AUTOSAR XML (schema 00049)
standard types defined: Boolean, SInt8, UInt32, Double, boolean, sint32, sint8, uint32, float64
package /Components
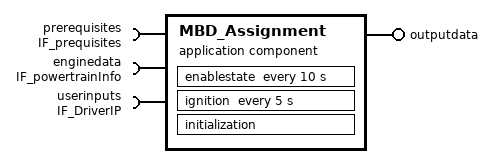
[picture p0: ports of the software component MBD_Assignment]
  application sw component type MBD_Assignment
    require port prerequisites: required-interface=IF_prequisites
      required-com-specs:
        data-element=IF_prequisites/DataElement1, init-value=0
        data-element=IF_prequisites/DataElement2, init-value=stowed
    require port enginedata: required-interface=IF_powertrainInfo
      required-com-specs:
        data-element=IF_powertrainInfo/DataElement1, init-value=neutral
        data-element=IF_powertrainInfo/DataElement2, init-value=0
    require port userinputs: required-interface=IF_DriverIP
      required-com-specs:
        data-element=IF_DriverIP/DataElement1, init-value=0
        data-element=IF_DriverIP/DataElement2, init-value=0
    provide port outputdata: provided-interface=outputdata
      provided-com-specs:
        data-element=outputdata/DataElement1, init-value=0
        data-element=outputdata/DataElement2, init-value=0
    behavior MBD_Assignment_IB: handle-termination-and-restart=NO-SUPPORT
      timing event Event: start-on-event=enablestate, period=10
      timing event Event1: start-on-event=ignition, period=5
      init event Event2: start-on-event=initialization
      implicit-inter-runnable-variables:
        data startenable: category=VALUE, sw-calibration-access=READ-ONLY, type=Boolean, init-value=0
      runnable enablestate
        data-read-access:
          5 x access:
            IN_userinputs_DataElement2: accessed-variable=userinputs.DataElement2
            IN_enginedata_DataElement1: accessed-variable=enginedata.DataElement1
            IN_enginedata_DataElement2: accessed-variable=enginedata.DataElement2
            IN_prerequisites_DataElement1: accessed-variable=prerequisites.DataElement1
            IN_prerequisites_DataElement2: accessed-variable=prerequisites.DataElement2
        written-local-variables:
          access WV_startenable: accessed-variable=startenable
      runnable ignition
        data-read-access:
          access IN_userinputs_DataElement1: accessed-variable=userinputs.DataElement1
        data-write-access:
          access OUT_outputdata_DataElement1: accessed-variable=outputdata.DataElement1
          access OUT_outputdata_DataElement2: accessed-variable=outputdata.DataElement2
        read-local-variables:
          access RV_startenable: accessed-variable=startenable
      runnable initialization
package /Components/SwcImplementations
  swc implementation MBD_Assignment_Impl: programming-language=C, sw-version=1.30.1, used-code-generator=Embedded Coder 7.9 (R2022b) 13-May-2022, vendor-id=0, behavior=MBD_Assignment_IB
    code-descriptors:
      code Code
        artifact-descriptors:
          short-label=MBD_Assignment_c, category=SWSRC
          short-label=MBD_Assignment_h, category=SWHDR
          short-label=MBD_Assignment_private_h, category=SWHDR
          short-label=MBD_Assignment_types_h, category=SWHDR
          short-label=rtwtypes_h, category=SWHDR
    resource consumption RsrcCons_MBD_Assignment
package /Interfaces
  4 x sender receiver interface:
    IF_prequisites
      data DataElement1: category=VALUE, sw-calibration-access=READ-ONLY, type=Boolean
      data DataElement2: category=VALUE, sw-calibration-access=READ-ONLY, type=StandPos
    IF_powertrainInfo
      data DataElement1: category=VALUE, sw-calibration-access=READ-ONLY, type=CurrentGear
      data DataElement2: category=VALUE, sw-calibration-access=READ-ONLY, type=UInt32
    IF_DriverIP
      data DataElement1: category=VALUE, sw-calibration-access=READ-ONLY, type=Boolean
      data DataElement2: category=VALUE, sw-calibration-access=READ-ONLY, type=SInt8
    outputdata
      data DataElement1: category=VALUE, sw-calibration-access=READ-ONLY, type=Double
      data DataElement2: category=VALUE, sw-calibration-access=READ-ONLY, type=Boolean
package /DataTypes
  impl type CurrentGear: category=VALUE, base-type=sint32, compu {0=neutral, 1=first, 2=second, 3=third, 4=fourth, 5=fifth, 6=sixth}
  impl type StandPos: category=VALUE, base-type=sint32, compu {0=stowed, 1=unstowed}
package /DataTypes/CompuMethods
  compu method COMPU_Boolean: 0=FALSE, 1=TRUE
package /DataTypes/Units
  unit NoUnit: factor-si-to-unit=1, offset-si-to-unit=0
package /Timing
  swc timing MBD_Assignment_timing: behavior=MBD_Assignment_IB
    timing-requirements:
      execution order constraint EOC
        ordered-elements:
          eoc executable entity ref ignition: executable=ignition, successor=enablestate
          eoc executable entity ref enablestate: executable=enablestate
